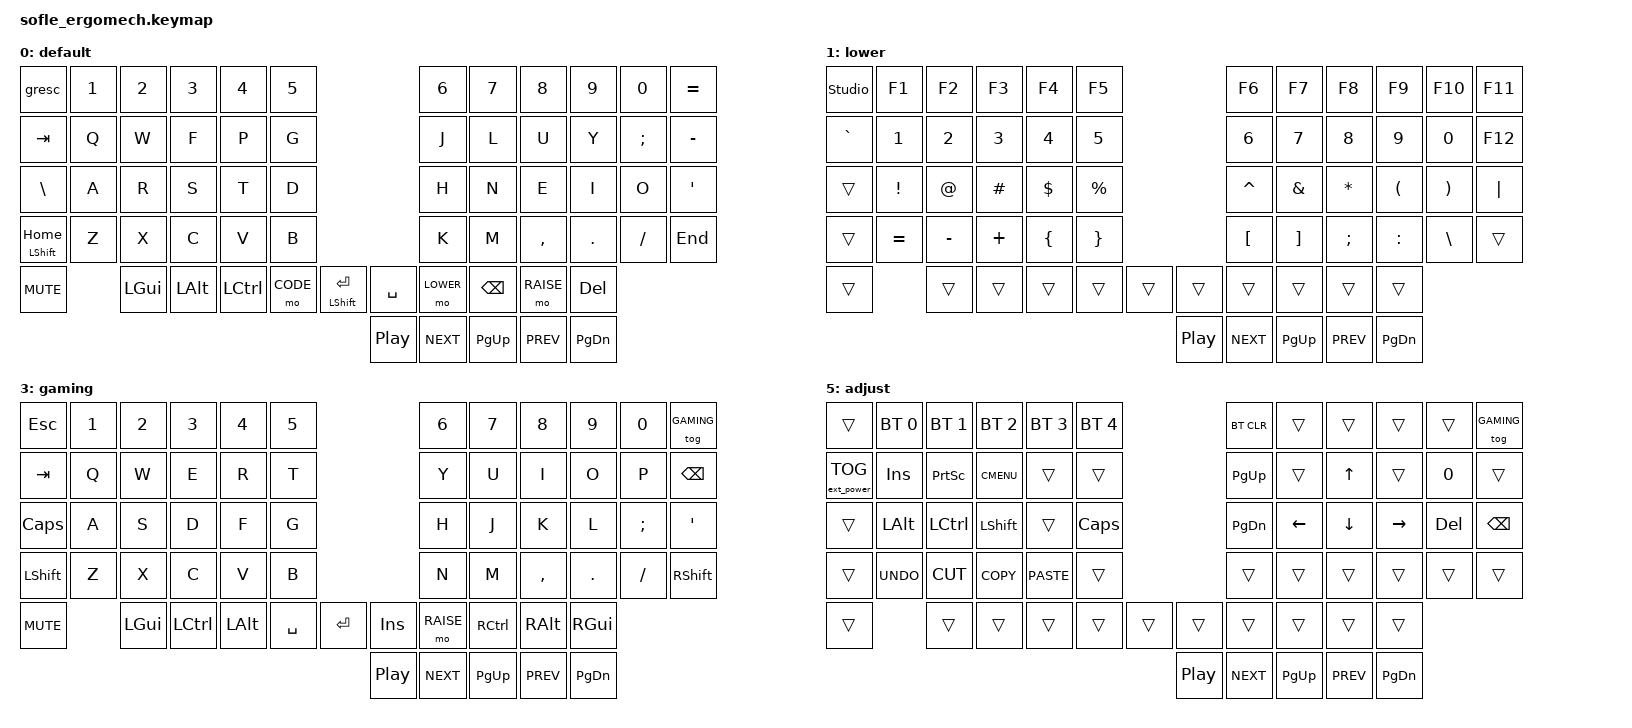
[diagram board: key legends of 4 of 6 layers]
/*
 * Copyright (c) 2020 The ZMK Contributors
 *
 * SPDX-License-Identifier: MIT
 */

#include <behaviors.dtsi>
#include <dt-bindings/zmk/bt.h>
#include <dt-bindings/zmk/ext_power.h>
#include <dt-bindings/zmk/keys.h>
#include <dt-bindings/zmk/rgb.h>

//mouse support and config
//#define ZMK_POINTING_DEFAULT_MOVE_VAL 1500  // default: 600
//#define ZMK_POINTING_DEFAULT_SCRL_VAL 20    // default: 10

#include <dt-bindings/zmk/pointing.h>


#define BASE 0
#define LOWER 1
#define RAISE 2
#define GAMING 3
#define CODE 4
#define ADJUST 5

/ {

   // Activate ADJUST layer by pressing raise and lower
    conditional_layers {
        compatible = "zmk,conditional-layers";

        adjust_layer {
            if-layers = <LOWER RAISE>;
            then-layer = <ADJUST>;
        };
    };

    keymap {
        compatible = "zmk,keymap";

        default_layer {
            display-name = "default";
// ------------------------------------------------------------------------------------------------------------
// | `ESC  |  1  |  2  |  3   |  4   |  5   |                   |  6   |  7    |  8    |  9   |   0   |  =/+  |
// |  TAB  |  Q  |  W  |  F   |  P   |  G   |                   |  J   |  L    |  U    |  Y   |   ;   |   -   |
// |   \   |  A  |  R  |  S   |  T   |  D   |                   |  H   |  N    |  E    |  I   |   O   |   '   |
// | SFTHME|  Z  |  X  |  C   |  V   |  B   |  MUTE  |  |       |  K   |  M    |  ,    |  .   |   /   | SHIFT |
//    | MUTE |   | GUI | ALT  | CTRL | CODE | SHFTEN |  | SPACE | LOWER| BKSP  | RAISE | DEL  |
//                                                      | Click - ply | > next | ^ PGUP | < prev | dwn PGDN |
            bindings = <
&gresc          &kp N1 &kp N2   &kp N3   &kp N4    &kp N5                               &kp N6    &kp N7    &kp N8    &kp N9   &kp N0   &kp EQUAL
&kp TAB         &kp Q  &kp W    &kp F    &kp P     &kp G                                &kp J     &kp L     &kp U     &kp Y    &kp SEMI &kp MINUS
&kp BSLH        &kp A  &kp R    &kp S    &kp T     &kp D                                &kp H     &kp N     &kp E     &kp I    &kp O    &kp SQT
&mt LSHIFT HOME &kp Z  &kp X    &kp C    &kp V     &kp B                                &kp K     &kp M     &kp COMMA &kp DOT  &kp FSLH &kp END
    &kp C_MUTE         &kp LGUI &kp LALT &kp LCTRL &mo CODE  &mt LSHIFT RET  &kp SPACE  &mo LOWER &kp BSPC  &mo RAISE &kp DEL
                                                                       &kp C_PP  &kp C_NEXT &kp PG_UP &kp C_PREV  &kp PG_DN
            >;

            sensor-bindings = <&inc_dec_kp C_VOL_DN C_VOL_UP>;
        };

        lower_layer {
            display-name = "lower";

            // TODO: Some binds are waiting for shifted keycode support.
            // ------------------------------------------------------------------------------------------------------------
            // |       |  F1 |  F2 |  F3  |  F4  |  F5  |                   |  F6  |  F7   |  F8   |  F9  |  F10  |  F11  |
            // |   `   |  1  |  2  |  3   |  4   |  5   |                   |  6   |  7    |  8    |  9   |   0   |  F12  |
            // |       |  !  |  @  |  #   |  $   |  %   |                   |  ^   |  &    |  *    |  (   |   )   |   |   |
            // |       |  =  |  -  |  +   |  {   |  }   |        |  |       |  [   |  ]    |  ;    |  :   |   \   |       |
            //               |     |      |      |      |        |  |       |      |       |       |      |
//                                                      | Click - ply | > next | ^ PGUP | < prev | dwn PGDN |

            bindings = <
&studio_unlock     &kp F1     &kp F2     &kp F3    &kp F4    &kp F5     &kp F6     &kp F7    &kp F8     &kp F9     &kp F10   &kp F11
&kp GRAVE  &kp N1     &kp N2     &kp N3    &kp N4    &kp N5     &kp N6     &kp N7    &kp N8     &kp N9     &kp N0    &kp F12
&trans     &kp EXCL   &kp AT     &kp HASH  &kp DLLR  &kp PRCNT  &kp CARET  &kp AMPS  &kp ASTRK  &kp LPAR   &kp RPAR  &kp PIPE
&trans     &kp EQUAL  &kp MINUS  &kp PLUS  &kp LBRC  &kp RBRC   &kp LBKT   &kp RBKT  &kp SEMI   &kp COLON  &kp BSLH  &trans
&trans     &trans     &trans     &trans    &trans    &trans     &trans     &trans    &trans     &trans     &trans
                                                                &kp C_PP  &kp C_NEXT &kp PG_UP &kp C_PREV  &kp PG_DN
            >;

            sensor-bindings = <&inc_dec_kp C_VOL_DN C_VOL_UP>;
        };

        raise_layer {
            display-name = "raise";
// ------------------------------------------------------------------------------------------------------------
// |      |      |       |      |       |       |                |      |      |       |      |       |       |
// |       | INS  | PSCR | GUI   |       |      |                | PGUP |      |   ^   |      |       |       |
// |       | ALT  | CTRL | SHIFT |       | CAPS |                | PGDN |   <- |   v   |  ->  |  DEL  | BKSPC |
// |       | UNDO | CUT  | COPY  | PASTE |      |      |  |      |      |      |       |      |       |       |
//                |      |       |       |      |      |  |      |      |      |       |      |
//                                                      | Click - ply | > next | ^ PGUP | < prev | dwn PGDN |
            bindings = <
&trans     &trans       &trans       &trans       &trans       &trans                        &trans    &trans    &trans   &trans    &trans  &trans
&trans     &kp INS      &kp PSCRN    &kp K_CMENU  &trans       &trans                        &kp PG_UP &trans    &kp UP   &trans    &kp N0  &trans
&trans     &kp LALT     &kp LCTRL    &kp LSHFT    &trans       &kp CLCK                      &kp PG_DN &kp LEFT  &kp DOWN &kp RIGHT &kp DEL &kp BSPC
&trans     &kp K_UNDO   &kp K_CUT    &kp K_COPY   &kp K_PASTE  &trans                        &trans    &trans    &trans   &trans    &trans  &trans
                        &trans       &trans       &trans       &trans        &trans  &trans  &trans    &trans    &trans   &trans
                                                                       &kp C_PP  &kp C_NEXT &kp PG_UP &kp C_PREV  &kp PG_DN
            >;

            sensor-bindings = <&inc_dec_kp C_VOL_DN C_VOL_UP>;
        };

        gaming_layer {
            display-name = "gaming";
// ------------------------------------------------------------------------------------------------------------
// |  ESC  |  1  |  2  |  3   |  4   |  5   |                   |  6   |  7    |  8    |  9   |   0   | BASE  |
// |  TAB  |  Q  |  W  |  E   |  R   |  T   |                   |  Y   |  U    |  I    |  O   |   P   | BKSPC |
// | CAPS  |  A  |  S  |  D   |  F   |  G   |                   |  H   |  J    |  K    |  L   |   ;   |   '   |
// | SHIFT |  Z  |  X  |  C   |  V   |  B   |  MUTE  |  |       |  N   |  M    |  ,    |  .   |   /   | SHIFT |
//               | GUI | CTRL | ALT  | SPACE|  ENTER |  | SPACE | RAISE| CTRL  | ALT   | GUI  |
//                                                      | Click - ply | > next | ^ PGUP | < prev | dwn PGDN |
            bindings = <
&kp ESC   &kp N1 &kp N2   &kp N3    &kp N4    &kp N5                              &kp N6     &kp N7    &kp N8    &kp N9   &kp N0   &tog GAMING
&kp TAB   &kp Q  &kp W    &kp E     &kp R     &kp T                               &kp Y      &kp U     &kp I     &kp O    &kp P    &kp BSPC
&kp CLCK  &kp A  &kp S    &kp D     &kp F     &kp G                               &kp H      &kp J     &kp K     &kp L    &kp SEMI &kp SQT
&kp LSHFT &kp Z  &kp X    &kp C     &kp V     &kp B                               &kp N      &kp M     &kp COMMA &kp DOT  &kp FSLH &kp RSHFT
        &kp C_MUTE &kp LGUI &kp LCTRL &kp LALT  &kp SPACE  &kp RET       &kp INS    &mo RAISE  &kp RCTRL &kp RALT  &kp RGUI
                                                                       &kp C_PP  &kp C_NEXT &kp PG_UP &kp C_PREV  &kp PG_DN
            >;

            sensor-bindings = <&inc_dec_kp C_VOL_DN C_VOL_UP>;
        };

        code_layer {
            display-name = "code";
// ------------------------------------------------------------------------------------------------------------
// |  ESC   |  1   |  2   |  3    |   4   |  5   |                | 6    |  /  |   *   |  -  |       |   =   |
// |        | INS  | PSCR | GUI   |       |      |                | PGUP |  7  |   8   |  9  |       |       |
// | CAPSWD | ALT  | CTRL | SHIFT |       | CAPS |                | PGDN |  4  |   5   |  6  |  DEL  | BKSPC |
// |        | UNDO | CUT  | COPY  | PASTE |      |      |  |      |      |  1  |   2   |  3  |       |       |
//                 |      |       |       |      | RCLK |  |      |      |  0  |   .   | BKSP|
//                                                      | Click - LCLK | > msRIGHT | ^ msUP | < msLEFT | dwn msDN |
            bindings = <
&kp BSPC   &kp N1       &kp N2    &kp N3       &kp N4       &kp N5                        &kp ESC   &kp LNLCK &kp FSLH  &kp KP_MULTIPLY &kp MINUS    &kp EQUAL
&kp DEL    &kp INS      &kp PSCRN &kp UP       &trans       &trans                        &kp PG_UP &kp N7    &kp N8    &kp N9          &kp KP_PLUS  &trans
&caps_word &kp LALT     &kp LEFT  &kp DOWN     &kp RIGHT    &kp CLCK                      &kp PG_DN &kp N4    &kp N5    &kp N6          &kp DEL      &kp BSPC
&trans     &kp K_UNDO   &kp K_CUT &kp K_COPY   &kp K_PASTE  &trans                        &trans    &kp N1    &kp N2    &kp N3          &trans       &trans
           &trans       &trans    &trans       &trans       &mkp RCLK &trans &kp KP_EQUAL &kp BSPC  &kp N0    &kp N0    &kp DOT         &kp DEL
                                                                     &mkp LCLK &mmv MOVE_RIGHT &mmv MOVE_UP &mmv MOVE_LEFT  &mmv MOVE_DOWN
            >;

            sensor-bindings = <&inc_dec_kp C_VOL_DN C_VOL_UP>;
        };

        adjust_layer {
            display-name = "adjust";
// ------------------------------------------------------------------------------------------------------------
// |       | BT1  | BT2  |  BT3  |  BT4  |  BT5 |                | BTCLR |      |       |      |       | GAMING |
// | EXTPW | INS  | PSCR | GUI   |       |      |                | PGUP  |      |   ^   |      |       |        |
// |       | ALT  | CTRL | SHIFT |       | CAPS |                | PGDN  |   <- |   v   |  ->  |  DEL  | BKSPC  |
// |       | UNDO | CUT  | COPY  | PASTE |      |      |  |      |       |      |       |      |       |        |
//                |      |       |       |      |      |  |      |       |      |       |      |
            bindings = <
&trans            &bt BT_SEL 0 &bt BT_SEL 1 &bt BT_SEL 2 &bt BT_SEL 3 &bt BT_SEL 4                  &bt BT_CLR    &trans    &trans   &trans    &trans  &tog GAMING
&ext_power EP_TOG &kp INS      &kp PSCRN    &kp K_CMENU  &trans       &trans                        &kp PG_UP &trans    &kp UP   &trans    &kp N0  &trans
&trans            &kp LALT     &kp LCTRL    &kp LSHFT    &trans       &kp CLCK                      &kp PG_DN &kp LEFT  &kp DOWN &kp RIGHT &kp DEL &kp BSPC
&trans            &kp K_UNDO   &kp K_CUT    &kp K_COPY   &kp K_PASTE  &trans        &trans          &trans    &trans    &trans   &trans    &trans  &trans
                        &trans       &trans       &trans       &trans        &trans  &trans  &trans    &trans    &trans   &trans
                                                                       &kp C_PP  &kp C_NEXT &kp PG_UP &kp C_PREV  &kp PG_DN
            >;

            sensor-bindings = <&inc_dec_kp C_VOL_DN C_VOL_UP>;
        };
    };
};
